# STM32G061 register map
File version: 1.4
CPU: CM0 r0p1, little endian, MPU, no FPU, 2 interrupt priority bits
Registers are 32-bit, read-write, reset 0x0 unless marked. A register's access mark holds for its fields unless they carry their own. Offsets are from the block's base; [hi:lo] are bit positions; {n}, {i} and the like mark numbered series; 'fields as' and 'values as' point back to an identical list.

## EXTI — External interrupt/event controller
Base 0x40021800
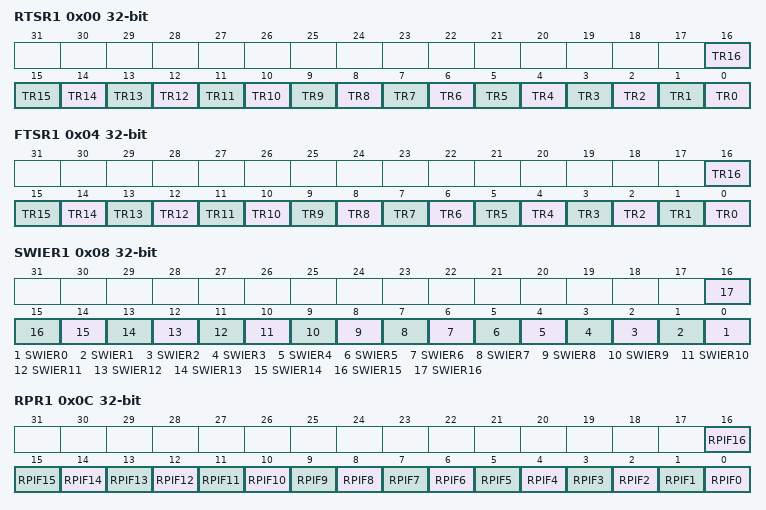
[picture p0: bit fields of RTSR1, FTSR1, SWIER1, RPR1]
0x00 RTSR1 — EXTI rising trigger selection register
  [all] fields
    0=Disabled (Rising edge trigger is disabled); 1=Enabled (Rising edge trigger is enabled)
  [n] TR{n} (n=0..16) — Rising trigger event configuration bit of Configurable Event input
0x04 FTSR1 — EXTI falling trigger selection register
  [all] fields
    0=Disabled (Falling edge trigger is disabled); 1=Enabled (Falling edge trigger is enabled)
  [n] TR{n} (n=0..16) — Rising trigger event configuration bit of Configurable Event input
0x08 SWIER1 — EXTI software interrupt event register
  [all] fields
    on write: 1=Pend (Generates an interrupt request)
  [n] SWIER{n} (n=0..16) — Rising trigger event configuration bit of Configurable Event input
0x0C RPR1 — EXTI rising edge pending register
  [all] fields
    on read: 0=NotPending (No trigger request occurred); 1=Pending (Selected trigger request occurred) | on write: 1=Clears pending bit
  [n] RPIF{n} write-1-clears (n=6..16) — configurable event inputs x rising edge Pending bit.
  [5] RPIF5 write-1-clears — configurable event inputs x rising edge Pending bit
  [n] RPIF{n} write-1-clears (n=0..4) — configurable event inputs x rising edge Pending bit.
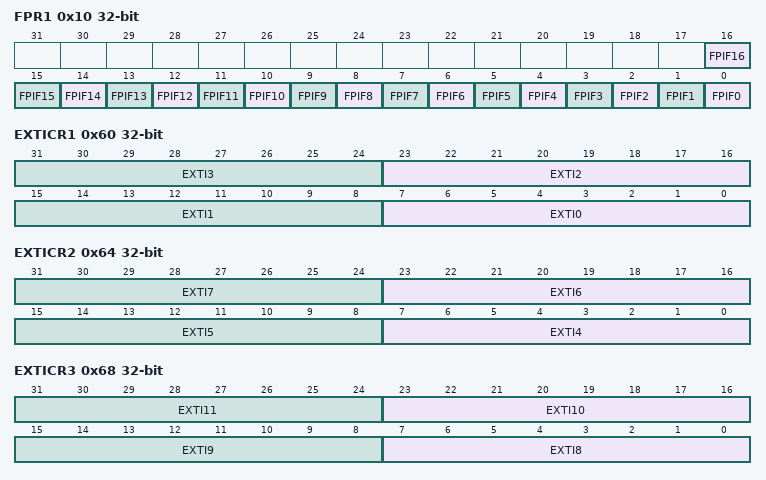
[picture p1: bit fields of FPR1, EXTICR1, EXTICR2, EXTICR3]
0x10 FPR1 — EXTI falling edge pending register
  [all] fields
    values as the fields of RPR1
  [n] FPIF{n} write-1-clears (n=0..16) — configurable event inputs x falling edge pending bit.
0x60 EXTICR1 — EXTI external interrupt selection register
  [all] fields
    0=PA (Select PAx as the source input for the EXTIx external interrupt); 1=PB (Select PBx as the source input for the EXTIx external interrupt); 2=PC (Select PCx as the source input for the EXTIx external interrupt); 3=PD (Select PDx as the source input for the EXTIx external interrupt); 5=PF (Select PFx as the source input for the EXTIx external interrupt)
  [8n+7:8n] EXTI{n} (n=0..3) — GPIO port selection
0x64 EXTICR2 — EXTI external interrupt selection register
  [all] fields
    values as the fields of EXTICR1
  [8n-25:8n-32] EXTI{n} (n=4..7) — GPIO port selection
0x68 EXTICR3 — EXTI external interrupt selection register
  [all] fields
    values as the fields of EXTICR1
  [8n-57:8n-64] EXTI{n} (n=8..11) — GPIO port selection
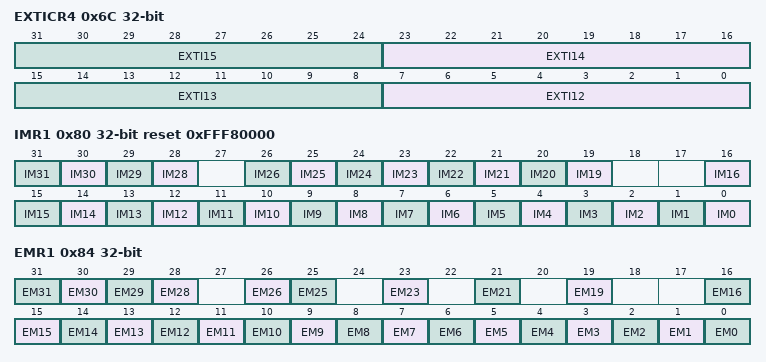
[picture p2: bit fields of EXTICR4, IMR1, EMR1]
0x6C EXTICR4 — EXTI external interrupt selection register
  [all] fields
    values as the fields of EXTICR1
  [8n-89:8n-96] EXTI{n} (n=12..15) — GPIO port selection
0x80 IMR1 reset 0xFFF80000 — EXTI CPU wakeup with interrupt mask register
  [all] fields
    0=Masked (Interrupt request line is masked); 1=Unmasked (Interrupt request line is unmasked)
  [n] IM{n} (n=28..31) — CPU wakeup with interrupt mask on event input
  [n] IM{n} (n=19..26) — CPU wakeup with interrupt mask on event input
  [n] IM{n} (n=0..16) — CPU wakeup with interrupt mask on event input
0x84 EMR1 — EXTI CPU wakeup with event mask register
  [all] fields
    0=Masked (Event request line is masked); 1=Unmasked (Event request line is unmasked)
  [n] EM{n} (n=28..31) — CPU wakeup with event mask on event input
  [26] EM26 — CPU wakeup with event mask on event input
  [25] EM25 — CPU wakeup with event mask on event input
  [23] EM23 — CPU wakeup with event mask on event input
  [21] EM21 — CPU wakeup with event mask on event input
  [19] EM19 — CPU wakeup with event mask on event input
  [n] EM{n} (n=0..16) — CPU wakeup with event mask on event input

## GPIOA — General-purpose I/Os
Base 0x50000000
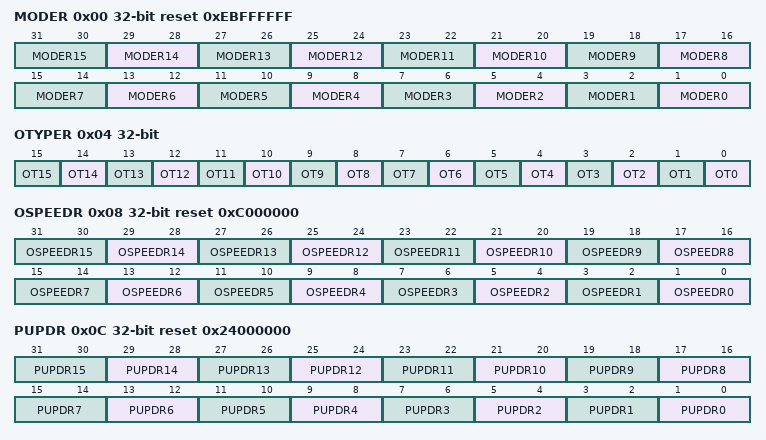
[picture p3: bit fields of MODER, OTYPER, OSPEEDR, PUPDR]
0x00 MODER reset 0xEBFFFFFF — GPIO port mode register
  [2n+1:2n] MODER{n} (n=0..15) — Port x configuration pin {n}
    0=Input mode; 1=Output (General purpose output mode); 2=Alternate function mode; 3=Analog mode
0x04 OTYPER — GPIO port output type register
  [n] OT{n} (n=0..15) — Port x configuration pin {n}
    0=PushPull (Output push-pull (reset state)); 1=OpenDrain (Output open-drain)
0x08 OSPEEDR reset 0xC000000 — GPIO port output speed register
  [2n+1:2n] OSPEEDR{n} (n=0..15) — Port x configuration pin {n}
    0=LowSpeed; 1=MediumSpeed; 2=HighSpeed; 3=VeryHighSpeed
0x0C PUPDR reset 0x24000000 — GPIO port pull-up/pull-down register
  [2n+1:2n] PUPDR{n} (n=0..15) — Port x configuration pin {n}
    0=Floating (No pull-up, pull-down); 1=PullUp; 2=PullDown
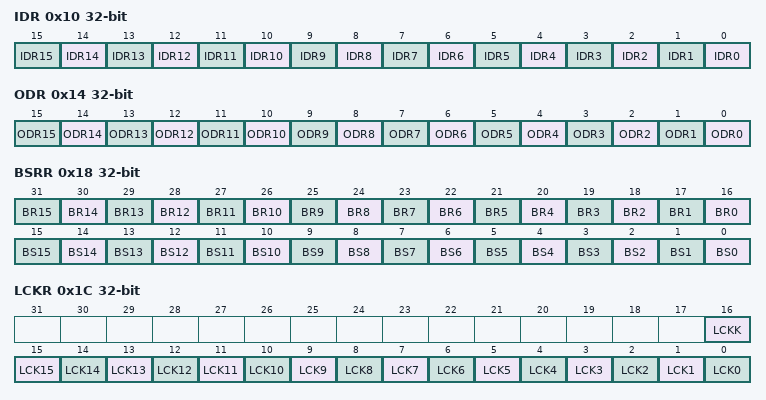
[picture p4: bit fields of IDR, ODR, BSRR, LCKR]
0x10 IDR ro — GPIO port input data register
  [n] IDR{n} (n=0..15) — Port input data pin {n}
    0=Low (Input is logic low); 1=High (Input is logic high)
0x14 ODR — GPIO port output data register
  [n] ODR{n} (n=0..15) — Port output data pin {n}
    0=Low (Set output to logic low); 1=High (Set output to logic high)
0x18 BSRR wo — GPIO port bit set/reset register
  [n+16] BR{n} (n=0..15) — Port x reset pin {n}
    1=Resets the corresponding ODx bit
  [n] BS{n} (n=0..15) — Port x set pin {n}
    1=Set (Sets the corresponding ODx bit)
0x1C LCKR — GPIO port configuration lock register
  [16] LCKK — Port x lock bit y (y= 0..15)
    0=NotActive (Port configuration lock key not active); 1=Active (Port configuration lock key active)
  [n] LCK{n} (n=0..15) — Port x lock pin {n}
    0=Unlocked (Port configuration not locked); 1=Locked (Port configuration locked)
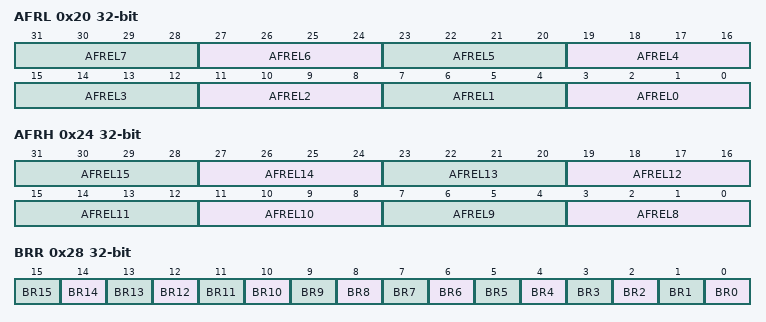
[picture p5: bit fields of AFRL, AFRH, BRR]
0x20 AFRL — GPIO alternate function low register
  [3:0] AFR{x} (x=EL0,EL1,EL2,EL3,EL4,EL5,EL6,EL7; step 4) — Alternate function selection for port x bit y (y = 0..7)
    {v}=AF{v} (v=0..7)
0x24 AFRH — GPIO alternate function high register
  [3:0] AFR{x} (x=EL8,EL9,EL10,EL11,EL12,EL13,EL14,EL15; step 4) — Alternate function selection for port x bit y (y = 8..15)
    {v}=AF{v} (v=0..7)
0x28 BRR wo — port bit reset register
  [n] BR{n} (n=0..15) — Port x reset pin {n}
    0=No action on the corresponding ODx bit; 1=Reset the ODx bit

## GPIOB — General-purpose I/Os
Base 0x50000400
Same registers: GPIOC 0x50000800, GPIOD 0x50000C00, GPIOE 0x50001000, GPIOF 0x50001400
Registers as GPIOA; these are added or differ:
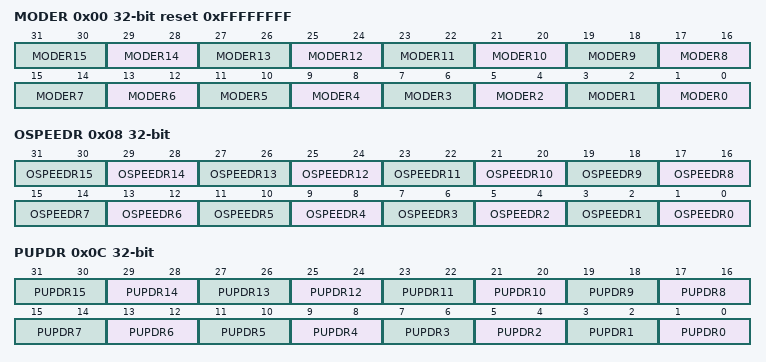
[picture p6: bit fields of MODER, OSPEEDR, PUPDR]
0x00 MODER reset 0xFFFFFFFF — GPIO port mode register
  [2n+1:2n] MODER{n} (n=0..15) — Port x configuration pin {n}
    0=Input mode; 1=Output (General purpose output mode); 2=Alternate function mode; 3=Analog mode
0x08 OSPEEDR — GPIO port output speed register
  [2n+1:2n] OSPEEDR{n} (n=0..15) — Port x configuration pin {n}
    0=LowSpeed; 1=MediumSpeed; 2=HighSpeed; 3=VeryHighSpeed
0x0C PUPDR — GPIO port pull-up/pull-down register
  [2n+1:2n] PUPDR{n} (n=0..15) — Port x configuration pin {n}
    0=Floating (No pull-up, pull-down); 1=PullUp; 2=PullDown
